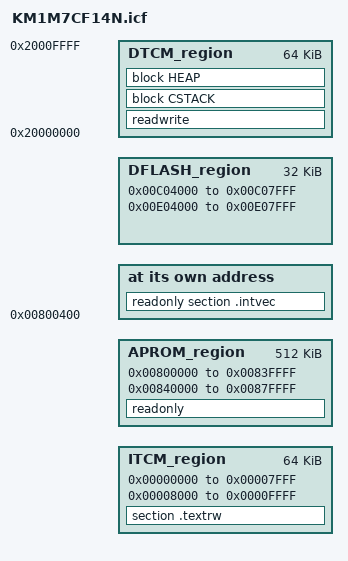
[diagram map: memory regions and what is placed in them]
/*###ICF### Section handled by ICF editor, don't touch! ****/
/*-Editor annotation file-*/
/* IcfEditorFile="$TOOLKIT_DIR$\config\ide\IcfEditor\cortex_v1_0.xml" */
/*-Specials-*/
define symbol __ICFEDIT_intvec_start__ = 0x00800400;
/*-Memory Regions-*/
define symbol __ICFEDIT_region_DTCM_start__                  = 0x20000000;
define symbol __ICFEDIT_region_DTCM_end__                    = 0x2000FFFF;
define symbol __ICFEDIT_region_DFLASH_BANK1_start__          = 0x00E04000;
define symbol __ICFEDIT_region_DFLASH_BANK1_end__            = 0x00E07FFF;
define symbol __ICFEDIT_region_DFLASH_BANK0_start__          = 0x00C04000;
define symbol __ICFEDIT_region_DFLASH_BANK0_end__            = 0x00C07FFF;
define symbol __ICFEDIT_region_APROM_BANK1_start__           = 0x00840000;
define symbol __ICFEDIT_region_APROM_BANK1_end__             = 0x0087FFFF;
define symbol __ICFEDIT_region_APROM_BANK0_start__           = 0x00800000;
define symbol __ICFEDIT_region_APROM_BANK0_end__             = 0x0083FFFF;
define symbol __ICFEDIT_region_ITCM_BANK1_start__            = 0x00008000;
define symbol __ICFEDIT_region_ITCM_BANK1_end__              = 0x0000FFFF;
define symbol __ICFEDIT_region_ITCM_BANK0_start__            = 0x00000000;
define symbol __ICFEDIT_region_ITCM_BANK0_end__              = 0x00007FFF;

/*-Sizes-*/
define symbol __ICFEDIT_size_cstack__ = 0x400;
define symbol __ICFEDIT_size_heap__   = 0x800;
/**** End of ICF editor section. ###ICF###*/

/**** Special settings for target device ****/

/* Define the memory space of 4G bytes named "mem" */
define memory mem with size = 4G;

/*- Define region in memory -*/
define region APROM_region               = mem:[from __ICFEDIT_region_APROM_BANK0_start__ to __ICFEDIT_region_APROM_BANK0_end__] | mem:[from __ICFEDIT_region_APROM_BANK1_start__ to __ICFEDIT_region_APROM_BANK1_end__];
define region DFLASH_region              = mem:[from __ICFEDIT_region_DFLASH_BANK0_start__ to __ICFEDIT_region_DFLASH_BANK0_end__] | mem:[from __ICFEDIT_region_DFLASH_BANK1_start__ to __ICFEDIT_region_DFLASH_BANK1_end__];
define region DTCM_region                = mem:[from __ICFEDIT_region_DTCM_start__ to __ICFEDIT_region_DTCM_end__];
define region ITCM_region                = mem:[from __ICFEDIT_region_ITCM_BANK0_start__ to __ICFEDIT_region_ITCM_BANK0_end__] | mem:[from __ICFEDIT_region_ITCM_BANK1_start__ to __ICFEDIT_region_ITCM_BANK1_end__];

/*- Define block -*/
define block CSTACK    with alignment = 8, size = __ICFEDIT_size_cstack__   { };
define block HEAP      with alignment = 8, size = __ICFEDIT_size_heap__     { };

/*- Initialize type -*/
initialize by copy { readwrite };
do not initialize  { section .noinit };

/*- Set placement in memory or region -*/
place at address mem:__ICFEDIT_intvec_start__ { readonly section .intvec };

place in APROM_region     { readonly };
place in DTCM_region      { readwrite, block CSTACK, block HEAP };
place in ITCM_region      { section .textrw };
